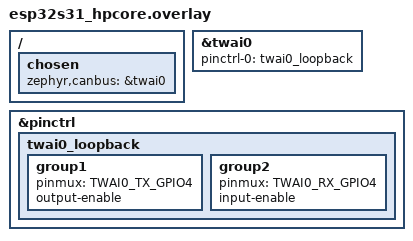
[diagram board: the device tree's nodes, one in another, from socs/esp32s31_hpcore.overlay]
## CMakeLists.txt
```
# SPDX-License-Identifier: Apache-2.0

cmake_minimum_required(VERSION 3.28.0)
find_package(Zephyr REQUIRED HINTS $ENV{ZEPHYR_BASE})
project(can_timing)

FILE(GLOB app_sources src/*.c)
target_sources(app PRIVATE ${app_sources})
```

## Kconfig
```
# Copyright (c) 2024 Vestas Wind Systems A/S
# SPDX-License-Identifier: Apache-2.0

mainmenu "CAN timing test"

config TEST_ALL_BITRATES
	bool "Test all CAN in Automation (CiA) recommended bitrates"
	help
	  Enable test of all bitrates recommended by CAN in Automation (CiA) regardless of the CAN
	  core clock frequency. Not all CAN controllers can meet all of the bitrates listed below,
	  and some board configurations may impose limits on which bitrates can be met due to
	  limitations in the CAN core clock frequency selection.

	  CiA 301 lists the following nominal bitrates as recommended:
	  - 10 kbit/s
	  - 20 kbit/s
	  - 50 kbit/s
	  - 125 kbit/s
	  - 250 kbit/s
	  - 500 kbit/s
	  - 800 kbit/s
	  - 1 Mbit/s

	  CiA 601-2 lists the following exemplary CAN FD data phase bitrates:
	  - 1.0 Mbit/s
	  - 2.0 Mbit/s
	  - 4.0 Mbit/s
	  - 5.0 Mbit/s
	  - 8.0 Mbit/s

	  CiA 601-3 recommends the following CAN FD core clock frequencies for good node
	  interoperability. The higher the frequency, the better:
	  - 20 MHz
	  - 40 MHz
	  - 80 MHz

	  If this option is not enabled and the core CAN clock frequency is not 80 MHz, the tests
	  will be limited to a historical, safe set of CAN bitrates.

source "Kconfig.zephyr"
```

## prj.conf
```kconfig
CONFIG_CAN=y
CONFIG_CAN_FD_MODE=y
CONFIG_TEST_USERSPACE=y
CONFIG_ZTEST=y
```

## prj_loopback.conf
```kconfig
CONFIG_CAN=y
CONFIG_ZTEST=y
CONFIG_CAN_LOOPBACK=y
```

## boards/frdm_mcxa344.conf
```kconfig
# Need short jp7 to disable debugger USB2CAN

CONFIG_TEST_ALL_BITRATES=y
```

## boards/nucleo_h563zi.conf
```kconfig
CONFIG_TEST_ALL_BITRATES=y
```

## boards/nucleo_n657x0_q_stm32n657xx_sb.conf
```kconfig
# SPDX-FileCopyrightText: Copyright The Zephyr Project Contributors
# SPDX-License-Identifier: Apache-2.0

CONFIG_TEST_ALL_BITRATES=y
CONFIG_TEST_USERSPACE=n
```

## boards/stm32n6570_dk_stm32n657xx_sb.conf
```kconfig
CONFIG_TEST_ALL_BITRATES=y
CONFIG_TEST_USERSPACE=n
```

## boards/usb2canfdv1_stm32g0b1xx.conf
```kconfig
# SPDX-FileCopyrightText: Copyright The Zephyr Project Contributors
# SPDX-License-Identifier: Apache-2.0

CONFIG_TEST_ALL_BITRATES=y
```

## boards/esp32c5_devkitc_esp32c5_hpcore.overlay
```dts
/*
 * Copyright (c) 2026 Espressif Systems (Shanghai) Co., Ltd.
 *
 * SPDX-License-Identifier: Apache-2.0
 */

/ {
	chosen {
		zephyr,canbus = &twai0;
	};
};

&twai0 {
	status = "okay";
	pinctrl-0 = <&twai0_default>;
	pinctrl-names = "default";
	bitrate = <500000>;
	bitrate-data = <1000000>;

	can-transceiver {
		max-bitrate = <5000000>;
	};
};
```

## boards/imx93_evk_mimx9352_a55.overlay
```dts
#include "imx93_evk_flexcan2.overlay"
```

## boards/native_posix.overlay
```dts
/*
 * Copyright (c) 2021 Vestas Wind Systems A/S
 *
 * SPDX-License-Identifier: Apache-2.0
 */

&can_loopback0 {
	status = "okay";
};
```

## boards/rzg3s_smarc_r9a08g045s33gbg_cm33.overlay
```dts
/ {
	chosen {
		zephyr,canbus = &canfd0;
	};
};

&canfd_global {
	status = "okay";
};

&gpio13{
	status = "okay";
};

&canfd0 {
	pinctrl-0 = <&can0_pins>;
	pinctrl-names = "default";
	status = "okay";
	rx-max-filters = <32>;
	phys = <&transceiver0>;
};
```

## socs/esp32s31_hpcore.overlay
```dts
/*
 * Copyright (c) 2026 Espressif Systems (Shanghai) Co., Ltd.
 *
 * SPDX-License-Identifier: Apache-2.0
 */

/ {
	chosen {
		zephyr,canbus = &twai0;
	};
};

&twai0 {
	status = "okay";
	pinctrl-0 = <&twai0_loopback>;
	pinctrl-names = "default";
};

&pinctrl {
	twai0_loopback: twai0_loopback {
		group1 {
			pinmux = <TWAI0_TX_GPIO4>;
			output-enable;	/* enable internal loopback */
		};

		group2 {
			pinmux = <TWAI0_RX_GPIO4>;
			input-enable;	/* enable internal loopback */
		};
	};
};
```

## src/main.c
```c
/*
 * Copyright (c) 2022-2024 Vestas Wind Systems A/S
 * Copyright (c) 2019 Alexander Wachter
 *
 * SPDX-License-Identifier: Apache-2.0
 */

#include <zephyr/drivers/can.h>
#include <zephyr/ztest.h>
#include <strings.h>

/**
 * @addtogroup t_driver_can
 * @{
 * @defgroup t_can_timing test_can_timing
 * @}
 */

/**
 * @brief Defines a set of CAN timing test values
 */
struct can_timing_test {
	/** Bitrate in bit/s */
	uint32_t bitrate;
	/** Desired sample point in permille */
	uint16_t sp;
	/** Historically safe bitrate test */
	bool historical;
};

/**
 * @brief List of CAN timing values to test.
 */
/* clang-format off */
static const struct can_timing_test can_timing_tests[] = {
	/* CiA 301 recommended bitrates */
	{   10000, 875, false },
	{   20000, 875, true },
	{   50000, 875, true },
	{  125000, 875, true },
	{  250000, 875, true },
	{  500000, 875, true },
	{  800000, 800, true },
	{ 1000000, 750, true },
};
/* clang-format on */

/**
 * @brief List of CAN FD data phase timing values to test.
 */
/* clang-format off */
static const struct can_timing_test can_timing_data_tests[] = {
	/* CiA 601-2 recommended data phase bitrates */
	{ 1000000, 750, true },
	{ 2000000, 750, false },
	{ 4000000, 750, false },
	{ 5000000, 750, false },
	{ 8000000, 750, false },
};
/* clang-format on */

/**
 * @brief Assert that a CAN timing struct matches the specified bitrate
 *
 * Assert that the values of a CAN timing struct matches the specified bitrate
 * for a given CAN controller device instance.
 *
 * @param dev pointer to the device structure for the driver instance
 * @param timing pointer to the CAN timing struct
 * @param bitrate the CAN bitrate in bit/s
 */
static void assert_bitrate_correct(const struct device *dev, struct can_timing *timing,
				   uint32_t bitrate)
{
	const uint32_t ts = 1 + timing->prop_seg + timing->phase_seg1 + timing->phase_seg2;
	uint32_t core_clock;
	uint32_t bitrate_calc;
	int err;

	zassert_not_equal(timing->prescaler, 0, "prescaler is zero");

	err = can_get_core_clock(dev, &core_clock);
	zassert_ok(err, "failed to get core CAN clock");

	bitrate_calc = core_clock / timing->prescaler / ts;
	zassert_equal(bitrate, bitrate_calc, "bitrate mismatch");
}

/**
 * @brief Assert that a CAN timing struct is within the bounds
 *
 * Assert that the values of a CAN timing struct are within the bounds for a
 * given CAN controller device instance.
 *
 * @param dev pointer to the device structure for the driver instance
 * @param timing pointer to the CAN timing struct
 */
static void assert_timing_within_bounds(struct can_timing *timing, const struct can_timing *min,
					const struct can_timing *max)
{
	zassert_true(timing->sjw <= max->sjw, "sjw exceeds max");
	zassert_true(timing->prop_seg <= max->prop_seg, "prop_seg exceeds max");
	zassert_true(timing->phase_seg1 <= max->phase_seg1, "phase_seg1 exceeds max");
	zassert_true(timing->phase_seg2 <= max->phase_seg2, "phase_seg2 exceeds max");
	zassert_true(timing->prescaler <= max->prescaler, "prescaler exceeds max");

	zassert_true(timing->sjw >= min->sjw, "sjw lower than min");
	zassert_true(timing->prop_seg >= min->prop_seg, "prop_seg lower than min");
	zassert_true(timing->phase_seg1 >= min->phase_seg1, "phase_seg1 lower than min");
	zassert_true(timing->phase_seg2 >= min->phase_seg2, "phase_seg2 lower than min");
	zassert_true(timing->prescaler >= min->prescaler, "prescaler lower than min");
}

/**
 * @brief Assert that a sample point is within a specified margin
 *
 * Assert that values of a CAN timing struct results in a specified sample point
 * within a given margin.
 *
 * @param timing pointer to the CAN timing struct
 * @param sp sample point in permille
 * @param sp_margin sample point margin in permille
 */
static void assert_sp_within_margin(struct can_timing *timing, uint16_t sp, uint16_t sp_margin)
{
	const uint32_t ts = 1 + timing->prop_seg + timing->phase_seg1 + timing->phase_seg2;
	const uint16_t sp_calc = ((1 + timing->prop_seg + timing->phase_seg1) * 1000) / ts;

	zassert_within(sp, sp_calc, sp_margin,
		       "sample point %d not within calculated sample point %d +/- %d", sp, sp_calc,
		       sp_margin);
}

/**
 * @brief Determine if a given bitrate test should be skipped.
 *
 * @param dev pointer to the device structure for the driver instance
 * @param test pointer to the set of CAN timing values
 */
bool skip_timing_value_test(const struct device *dev, const struct can_timing_test *test)
{
	uint32_t core_clock;
	int err;

	err = can_get_core_clock(dev, &core_clock);
	zassert_equal(err, 0, "failed to get core CAN clock");

	if (test->historical) {
		/* Historically safe test, never skip */
		return false;
	}

	if (core_clock == MHZ(80)) {
		/* No bitrates skipped when the CAN core clock is 80 MHz */
		return false;
	}

	if (IS_ENABLED(CONFIG_TEST_ALL_BITRATES)) {
		/* No bitrates skipped when all tests explicitly enabled */
		return false;
	}

	return true;
}

/**
 * @brief Test a set of CAN timing values
 *
 * Test a set of CAN timing values on a specified CAN controller device
 * instance.
 *
 * @param  dev pointer to the device structure for the driver instance
 * @param  test pointer to the set of CAN timing values
 * returns true if bitrate was supported, false otherwise
 */
static bool test_timing_values(const struct device *dev, const struct can_timing_test *test,
			       bool data_phase)
{
	const struct can_timing *max = NULL;
	const struct can_timing *min = NULL;
	struct can_timing timing = {0};
	int sp_err = -EINVAL;
	int err;

	printk("testing bitrate %u, sample point %u.%u%%: ", test->bitrate, test->sp / 10,
	       test->sp % 10);

	if (skip_timing_value_test(dev, test)) {
		printk("skipped\n");
		return false;
	}

	if (data_phase) {
		if (IS_ENABLED(CONFIG_CAN_FD_MODE)) {
			min = can_get_timing_data_min(dev);
			max = can_get_timing_data_max(dev);
			sp_err = can_calc_timing_data(dev, &timing, test->bitrate, test->sp);
		} else {
			zassert_unreachable("data phase timing test without CAN FD support");
		}
	} else {
		min = can_get_timing_min(dev);
		max = can_get_timing_max(dev);
		sp_err = can_calc_timing(dev, &timing, test->bitrate, test->sp);
	}

	if (sp_err == -ENOTSUP) {
		printk("bitrate not supported\n");
		return false;
	} else {
		zassert_true(sp_err >= 0, "unknown error %d", sp_err);
		zassert_true(sp_err <= CONFIG_CAN_SAMPLE_POINT_MARGIN,
			     "sample point error %d too large", sp_err);

		printk("sjw = %u, prop_seg = %u, phase_seg1 = %u, phase_seg2 = %u, prescaler = %u ",
		       timing.sjw, timing.prop_seg, timing.phase_seg1, timing.phase_seg2,
		       timing.prescaler);

		assert_bitrate_correct(dev, &timing, test->bitrate);
		assert_timing_within_bounds(&timing, min, max);
		assert_sp_within_margin(&timing, test->sp, CONFIG_CAN_SAMPLE_POINT_MARGIN);

		if (IS_ENABLED(CONFIG_CAN_FD_MODE) && data_phase) {
			err = can_set_timing_data(dev, &timing);
		} else {
			err = can_set_timing(dev, &timing);
		}
		zassert_ok(err, "failed to set timing (err %d)", err);

		printk("OK, sample point error %d.%d%%\n", sp_err / 10, sp_err % 10);
	}

	return true;
}

/**
 * @brief Test all CAN timing values
 */
ZTEST_USER(can_timing, test_timing)
{
	const struct device *const dev = DEVICE_DT_GET(DT_CHOSEN(zephyr_canbus));
	int count = 0;
	int i;

	for (i = 0; i < ARRAY_SIZE(can_timing_tests); i++) {
		if (test_timing_values(dev, &can_timing_tests[i], false)) {
			count++;
		}
	}

	zassert_true(count > 0, "no bitrates supported");
}

/**
 * @brief Test all CAN timing values for the data phase.
 */
ZTEST_USER(can_timing, test_timing_data)
{
	const struct device *const dev = DEVICE_DT_GET(DT_CHOSEN(zephyr_canbus));
	can_mode_t cap;
	int count = 0;
	int err;
	int i;

	err = can_get_capabilities(dev, &cap);
	zassert_ok(err, "failed to get CAN controller capabilities (err %d)", err);

	if ((cap & CAN_MODE_FD) == 0) {
		ztest_test_skip();
	}

	for (i = 0; i < ARRAY_SIZE(can_timing_data_tests); i++) {
		if (test_timing_values(dev, &can_timing_data_tests[i], true)) {
			count++;
		}
	}

	zassert_true(count > 0, "no data phase bitrates supported");
}

void *can_timing_setup(void)
{
	const struct device *const dev = DEVICE_DT_GET(DT_CHOSEN(zephyr_canbus));
	uint32_t core_clock;
	int err;

	zassert_true(device_is_ready(dev), "CAN device not ready");
	k_object_access_grant(dev, k_current_get());

	err = can_get_core_clock(dev, &core_clock);
	zassert_ok(err, "failed to get core CAN clock");

	printk("testing on device %s @ %u Hz, sample point margin +/-%u permille\n", dev->name,
	       core_clock, CONFIG_CAN_SAMPLE_POINT_MARGIN);

	if (IS_ENABLED(CONFIG_CAN_FD_MODE)) {
		can_mode_t cap;

		err = can_get_capabilities(dev, &cap);
		zassert_ok(err, "failed to get CAN controller capabilities (err %d)", err);

		if ((cap & CAN_MODE_FD) != 0) {
			switch (core_clock) {
			case MHZ(20):
				break;
			case MHZ(40):
				break;
			case MHZ(80):
				break;
			default:
				TC_PRINT("Warning: CiA 601-3 recommends a CAN FD core clock of "
					 "20, 40, or 80 MHz for good node interoperability\n");
				break;
			}
		}
	}

	if (IS_ENABLED(CONFIG_TEST_ALL_BITRATES) && core_clock != MHZ(80)) {
		TC_PRINT("Warning: Testing all bitrates with CAN core clock of %u Hz "
			 "(CONFIG_TEST_ALL_BITRATES=y)\n",
			 core_clock);
	}

	return NULL;
}

ZTEST_SUITE(can_timing, NULL, can_timing_setup, NULL, NULL, NULL);
```
